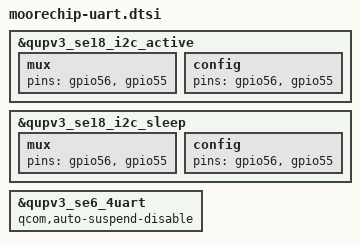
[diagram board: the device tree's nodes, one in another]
&qupv3_se18_i2c_active {
	mux {
		pins = "gpio56", "gpio55";
	};

	config {
		pins = "gpio56", "gpio55";
	};
};

&qupv3_se18_i2c_sleep {
	mux {
		pins = "gpio56", "gpio55";
	};

	config {
		pins = "gpio56", "gpio55";
	};
};

&qupv3_se6_4uart {
	qcom,auto-suspend-disable;
};
